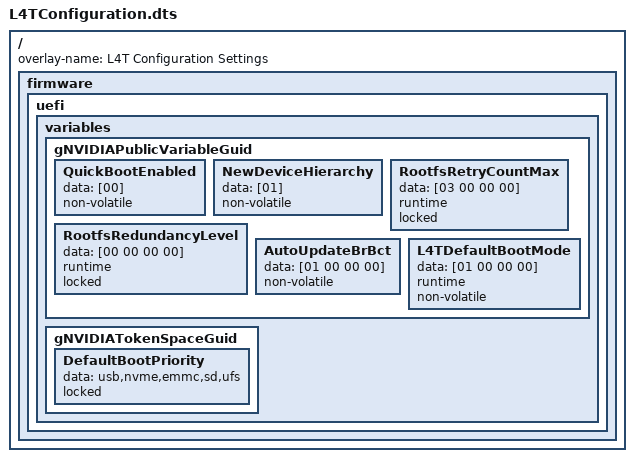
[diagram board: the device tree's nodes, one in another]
/** @file
*
*  Copyright (c) 2022, NVIDIA CORPORATION & AFFILIATES. All rights reserved.
*
*  SPDX-License-Identifier: BSD-2-Clause-Patent
*
**/

/dts-v1/;
/plugin/;

/ {
	overlay-name = "L4T Configuration Settings";

	fragment@0 {
		target-path = "/";
		board_config {
			sw-modules = "uefi";
		};

		__overlay__ {
			firmware {
				uefi {
					variables {
						gNVIDIAPublicVariableGuid {
							QuickBootEnabled {
								data = [00];
								non-volatile;
							};
							NewDeviceHierarchy {
								data = [01];
								non-volatile;
							};
							RootfsRetryCountMax {
								data = [03 00 00 00];
								runtime;
								locked;
							};
							RootfsRedundancyLevel {
								data = [00 00 00 00];
								runtime;
								locked;
							};
							AutoUpdateBrBct {
								data = [01 00 00 00];
								non-volatile;
							};
							L4TDefaultBootMode {
								data = [01 00 00 00];
								runtime;
								non-volatile;
							};
						};

						gNVIDIATokenSpaceGuid {
							DefaultBootPriority {
								data = "usb,nvme,emmc,sd,ufs";
								locked;
							};
						};
					};
				};
			};
		};
	};
};
